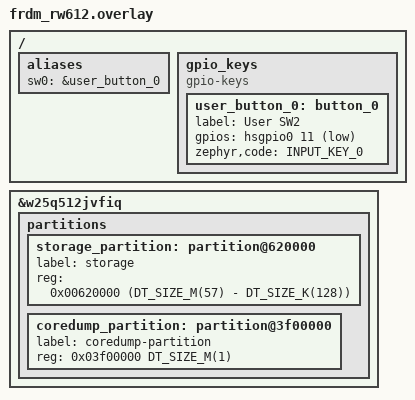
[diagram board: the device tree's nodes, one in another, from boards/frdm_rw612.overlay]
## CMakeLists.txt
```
cmake_minimum_required(VERSION 3.20.0)

if (EXISTS "${CMAKE_CURRENT_SOURCE_DIR}/credentials.conf")
  list(APPEND EXTRA_CONF_FILE "${CMAKE_CURRENT_SOURCE_DIR}/credentials.conf")
endif ()


# Board overlays use Zephyr 4.4 layouts; extend them for Zephyr 4.5 and newer.
find_package(Zephyr REQUIRED HINTS $ENV{ZEPHYR_BASE} COMPONENTS version)
if (KERNEL_VERSION_STRING VERSION_GREATER_EQUAL "4.5.0")
  set(coredump_board "${BOARD}")
  if (NOT coredump_board)
    set(coredump_board "$ENV{BOARD}")
  endif ()
  string(REGEX REPLACE "@[^/]*" "" coredump_board "${coredump_board}")
  string(REPLACE "/" "_" coredump_board "${coredump_board}")
  set(coredump_partition_overlay
      "${CMAKE_CURRENT_SOURCE_DIR}/boards/zephyr-4.5/${coredump_board}.overlay")
  if (EXISTS "${coredump_partition_overlay}")
    list(APPEND EXTRA_DTC_OVERLAY_FILE "${coredump_partition_overlay}")
  endif ()
endif ()

find_package(Zephyr REQUIRED HINTS $ENV{ZEPHYR_BASE})
project(coredumps)

add_subdirectory(../net-common ${CMAKE_CURRENT_BINARY_DIR}/net-common)

target_sources(app PRIVATE
        src/main.c
)
```

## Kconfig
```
config NET_WIFI_SSID
	string "SSID device should connect to"
	help
		SSID of the wifi network that the device should connect to.

config NET_WIFI_PASSWORD
	string "Wifi Password device should connect to"
	help
		Wifi password for the network that the device should connect to.

choice SPOTFLOW_NETWORK_IFACE
	prompt "Spotflow network interface"
	default SPOTFLOW_USE_WIFI

#By default, use WIFI for Spotflow samples (more common among example boards)
config SPOTFLOW_USE_WIFI
	bool "Enable Wifi for Spotflow samples"
	imply WIFI
	imply WIFI_NM
	imply NET_L2_WIFI_MGMT
	#nxp specific configs
	imply WIFI_NXP if BOARD_FRDM_RW612
	# Enables IP fragmentation, which fixes the TLS handshake issue in Zephyr 4.2
	imply NXP_WIFI_TX_RX_ZERO_COPY if NXP_RW610


config SPOTFLOW_USE_ETH
	bool "Enable Ethernet for Spotflow samples"
	imply ETH_DRIVER
	imply NET_L2_ETHERNET_MGMT

endchoice

config NET_IF_MAX_IPV4_COUNT
	int
	#by default eth driver on FRDM_RW612 is enabled;
	#therefore, we have to allow multiple IPv4 interfaces
	default 2 if SPOTFLOW_USE_WIFI && BOARD_FRDM_RW612

source "Kconfig.zephyr"
```

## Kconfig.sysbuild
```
config WIFI_NRF70
	default y if BOARD_NRF7002DK

source "${ZEPHYR_BASE}/share/sysbuild/Kconfig"
```

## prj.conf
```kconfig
# Boards that support both Wi-Fi and Ethernet use Wi-Fi by default.
# If you want to use Ethernet instead, please use the following option:
# CONFIG_SPOTFLOW_USE_ETH=y

# Enable logging and coredump sending to Spotflow
CONFIG_SPOTFLOW=y
CONFIG_SPOTFLOW_COREDUMPS=y

# Enable logging
CONFIG_LOG=y
CONFIG_LOG_RUNTIME_FILTERING=y

# Show function names in the logs
CONFIG_LOG_FUNC_NAME_PREFIX_INF=y
CONFIG_LOG_FUNC_NAME_PREFIX_WRN=y
CONFIG_LOG_FUNC_NAME_PREFIX_ERR=y

# Log Spotflow module details for debugging
CONFIG_SPOTFLOW_MODULE_DEFAULT_LOG_LEVEL=4

# Configure what should be included in the coredump
# (use CONFIG_DEBUG_COREDUMP_MEMORY_DUMP_MIN=y on boards with limited flash memory)
CONFIG_DEBUG_COREDUMP_THREADS_METADATA=y
CONFIG_DEBUG_COREDUMP_MEMORY_DUMP_THREADS=y

# Enable GPIO to enable a button to trigger a core dump
CONFIG_GPIO=y

# Satisfy networking dependencies of Spotflow
CONFIG_NETWORKING=y
CONFIG_NET_MGMT=y
CONFIG_NET_MGMT_EVENT=y
CONFIG_NET_MGMT_EVENT_INFO=y
CONFIG_NET_CONFIG_AUTO_INIT=n
CONFIG_NET_CONNECTION_MANAGER=y
CONFIG_NET_DHCPV4=y
CONFIG_NET_IPV4=y
CONFIG_NET_IPV6=n
CONFIG_NET_TCP=y
CONFIG_NET_UDP=y

# Increase main stack size for the sample
CONFIG_MAIN_STACK_SIZE=4096

# Persistence of configuration using Zephyr settings
CONFIG_FLASH=y
CONFIG_FLASH_MAP=y
CONFIG_NVS=y
CONFIG_SETTINGS=y
CONFIG_SETTINGS_NVS=y

# Ensures that connection is established even on boards without hardware random number generator.
# We recommend removing this option for production use.
CONFIG_MBEDTLS_PSA_CRYPTO_LEGACY_RNG=y
```

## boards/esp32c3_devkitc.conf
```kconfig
# WiFi Config
CONFIG_WIFI_ESP32=y
CONFIG_ESP32_WIFI_STA_AUTO_DHCPV4=y
CONFIG_ESP32_WIFI_STA_RECONNECT=y
CONFIG_NET_L2_ETHERNET=y

# esp32c3 devkitc has only 128 Kb available flash memory
CONFIG_DEBUG_COREDUMP_MEMORY_DUMP_MIN=y
#esp32c3 devkitc has only 400 KB RAM
CONFIG_HEAP_MEM_POOL_ADD_SIZE_SPOTFLOW_COREDUMPS=8192
CONFIG_SPOTFLOW_COREDUMPS_CHUNK_SIZE=1024
CONFIG_SPOTFLOW_COREDUMPS_BACKEND_QUEUE_SIZE=7
```

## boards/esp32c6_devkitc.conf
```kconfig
# WiFi Config
CONFIG_WIFI_ESP32=y
CONFIG_ESP32_WIFI_STA_AUTO_DHCPV4=y
CONFIG_ESP32_WIFI_STA_RECONNECT=y
CONFIG_NET_L2_ETHERNET=y

# not supported on esp32c6 devkitc
CONFIG_DEBUG_COREDUMP_THREADS_METADATA=n
```

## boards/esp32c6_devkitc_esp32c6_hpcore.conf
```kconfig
# Automatic Wi-Fi reconnection isn't enabled by default
CONFIG_ESP32_WIFI_STA_RECONNECT=y

# Not supported on this board
CONFIG_DEBUG_COREDUMP_THREADS_METADATA=n
```

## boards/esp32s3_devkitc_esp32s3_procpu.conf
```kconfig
# WiFi Config
CONFIG_WIFI_ESP32=y
CONFIG_ESP32_WIFI_STA_AUTO_DHCPV4=y
CONFIG_ESP32_WIFI_STA_RECONNECT=y
CONFIG_NET_L2_ETHERNET=y
```

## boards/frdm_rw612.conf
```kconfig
# These configs are automatically enabled for FRDM-RW612 board from Kconfig:
# WIFI_NXP
# NXP_WIFI_TX_RX_ZERO_COPY
# NET_IF_MAX_IPV4_COUNT=2

# Fix buffer size for RW612 on Zephyr 4.1.0+
CONFIG_NET_BUF_DATA_SIZE=256

CONFIG_NXP_WIFI_SOFTAP_SUPPORT=n
```

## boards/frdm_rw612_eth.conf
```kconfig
CONFIG_WIFI_NXP=n
CONFIG_NXP_RW610=y
CONFIG_ETH_DRIVER=y
CONFIG_NET_L2_ETHERNET_MGMT=y
```

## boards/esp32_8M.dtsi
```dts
/* Redefining coredump partition to be 1MB at the end of 8MB flash, see:
 * zephyr/dts/common/espressif/partitions_0x0_default_4M.dtsi
 */

/delete-node/ &coredump_partition;

&flash0 {
	partitions {
		#address-cells = <1>;
		#size-cells = <1>;

		/* New coredump partition: 1MB at the end of 8MB flash */
		coredump_partition: partition@0x700000{
			label = "coredump-partition";
			reg = <0x700000 DT_SIZE_M(1)>;
		};
	};
};
```

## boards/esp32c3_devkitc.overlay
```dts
&wifi {
	status = "okay";
};

/delete-node/ &coredump_partition;

&flash0 {
	partitions {
		#address-cells = <1>;
		#size-cells = <1>;

		/* Remove the scratch partition if present (Zephyr 4.4 and older). */
		/delete-node/ partition@3e0000;

		/* reserve 128 KB at top of 4 MB flash for core dumps */
		/*128 - because we got 124 from deleted scratch partition
		* and 4 from previous coredump partition */
		coredump_partition: partition@3e0000{
			label = "coredump-partition";
			reg = <0x3e0000 DT_SIZE_K(128)>;
		};
	};
};
```

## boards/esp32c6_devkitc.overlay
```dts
#include "esp32_8M.dtsi"

&wifi {
	status = "okay";
};
```

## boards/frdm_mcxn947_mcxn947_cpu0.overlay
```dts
/* External flash chip - Winbond */
&w25q64jvssiq {
	partitions {
		storage_partition: partition@0 {
			label = "storage";
			reg = <0x0 0x100000>; /* first 1MB of 8 MB flash */
		};
		coredump_partition: partition@700000 {
			label = "coredump-partition";
			reg = <0x700000 0x100000>; /* last 1MB of 8 MB flash */
		};
	};
};
```

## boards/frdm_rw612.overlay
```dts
/* GPIO not available in 4.1.0, adding based on commit
 * https://github.com/zephyrproject-rtos/zephyr/commit/2df6b7fd2dea95105b3598c41fecbd7089fab080
 */
#include <zephyr/dt-bindings/input/input-event-codes.h>
/ {
	aliases {
		/* make an alias so we can refer to “sw0” in code */
		sw0 = &user_button_0;
	};

	gpio_keys {
		compatible = "gpio-keys";
		user_button_0: button_0 {
			label = "User SW2";
			gpios = <&hsgpio0 11 (GPIO_ACTIVE_LOW | GPIO_PULL_UP)>;
			zephyr,code = <INPUT_KEY_0>;
			status = "okay";
		};
	};
};

/* External flash chip - Winbond */
&w25q512jvfiq {
	partitions {
		/* Reducing size by 1 MB to leave space for coredump */
		storage_partition: partition@620000 {
			label = "storage";
			reg = <0x00620000 (DT_SIZE_M(57) - DT_SIZE_K(128))>;
		};

		/* Last 1MB of 64 MB flash */
		coredump_partition: partition@3f00000 {
			label = "coredump-partition";
			reg = <0x03f00000 DT_SIZE_M(1)>;
		};
	};
};
```

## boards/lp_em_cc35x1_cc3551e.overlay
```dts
/delete-node/ &storage_partition;

&wlan0 {
	status = "okay";
};

&flash2 {
	partitions {
		storage_partition: partition@8000 {
			label = "storage";
			reg = <0x00008000 0x00004000>;
		};

		coredump_partition: partition@c000 {
			label = "coredump-partition";
			reg = <0x0000c000 0x0001f000>;
		};
	};
};
```

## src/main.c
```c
#include <zephyr/kernel.h>
#include <zephyr/logging/log.h>

#include "zephyr/debug/coredump.h"

#include "zephyr/drivers/gpio.h"

#include "net.h"

LOG_MODULE_REGISTER(MAIN, LOG_LEVEL_INF);

#define SW0_NODE DT_ALIAS(sw0)
#if !DT_NODE_HAS_STATUS_OKAY(SW0_NODE)
#error "Unsupported board: sw0 devicetree alias is not defined"
#endif

static const struct gpio_dt_spec button = GPIO_DT_SPEC_GET_OR(SW0_NODE, gpios, { 0 });
static struct gpio_callback button_cb_data;

static int prepare_button();

int main(void)
{
	LOG_INF("Starting Spotflow logging example");
	LOG_INF("Press button to oops the device. "
		"Coredump will be created and sent to Spotflow on reboot.");
	int ret;
	ret = prepare_button();
	if (ret != 0) {
		LOG_ERR("Failed to prepare button, exiting");
		return ret;
	}

	// Wait for the initialization of network device
	k_sleep(K_SECONDS(1));

	spotflow_sample_net_init();

	int i = 0;
	while (true) {
		LOG_INF("Hello from Zephyr to Spotflow: %d", i++);
		k_sleep(K_SECONDS(2));
	}
}

static void button_pressed(const struct device* dev, struct gpio_callback* cb, uint32_t pins)
{
	LOG_INF("Button pressed. Going to oops.");
	k_oops();
}

static int prepare_button()
{
	int ret;
	if (!gpio_is_ready_dt(&button)) {
		LOG_ERR("Error: button device %s is not ready", button.port->name);
		return -EINVAL;
	}

	ret = gpio_pin_configure_dt(&button, GPIO_INPUT);
	if (ret != 0) {
		LOG_ERR("Error %d: failed to configure %s pin %d", ret, button.port->name,
			button.pin);
		return ret;
	}

	ret = gpio_pin_interrupt_configure_dt(&button, GPIO_INT_EDGE_TO_ACTIVE);
	if (ret != 0) {
		LOG_ERR("Error %d: failed to configure interrupt on %s pin %d", ret,
			button.port->name, button.pin);
		return ret;
	}

	gpio_init_callback(&button_cb_data, button_pressed, BIT(button.pin));
	gpio_add_callback(button.port, &button_cb_data);

	LOG_DBG("Set up button at %s pin %d", button.port->name, button.pin);
	return 0;
}
```
